# MMC1 register map
Vendor: Texas Instruments
Registers are 32-bit, access per field, reset 0x0 unless marked. A register's access mark holds for its fields unless they carry their own. Offsets are as the file gives them; [hi:lo] are bit positions; {n}, {i} and the like mark numbered series.

## MMC1 (part 2 of 3)
0x00 MMCHS_HL_REV ro reset not defined — IP Revision Identifier (X.Y.R) Used by software to track features, bugs, and compatibility
  [31:0] REVISION — IP Revision
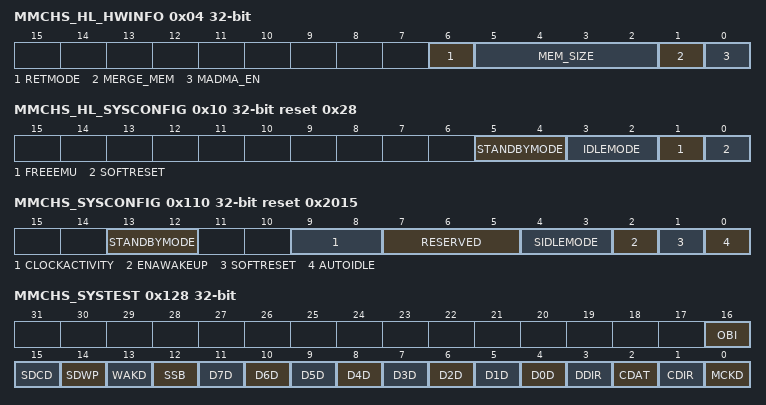
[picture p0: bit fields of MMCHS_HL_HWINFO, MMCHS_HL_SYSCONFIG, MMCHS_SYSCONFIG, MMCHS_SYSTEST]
0x04 MMCHS_HL_HWINFO ro reset not defined — Information about the IP module's hardware configuration.
  [6] RETMODE — Retention Mode generic parameter This bit field indicates whether the retention mode is supported using the pin PIRFFRET.
    1=RetEnabled (Retention mode enabled); 0=RetDisabled (Retention mode disabled)
  [5:2] MEM_SIZE — Memory size for FIFO buffer:
    2=MEM_1024 (Memory of 1024 bytes, max block length is 1024 bytes); 1=MEM_512 (Memory of 512 bytes, max block length is 512 bytes); 8=MEM_4096 (Memory of 4096 bytes, max block length is 2048 bytes); 4=MEM_2048 (Memory of 2048 bytes, max block length is 2048 bytes)
  [1] MERGE_MEM — Memory merged for FIFO buffer: This register defines the configuration of FIFO buffer architecture. If the bit is set STA and DFT shall support clock multiplexing and balancing.
    1=SingleMemBuffer (A single memory is used with multiplexed addresses, data and clocks.); 0=TwoMemBuffer (2 memories instantiated, one per data transfer direction.)
  [0] MADMA_EN — Master DMA enabled generic parameter: This register defines the configuration of the controller to know if it supports the master DMA management called ADMA.
    1=SupportADMA (Controller supports ADMA); 0=No Master DMA (ADMA) management supported
0x10 MMCHS_HL_SYSCONFIG reset 0x28 — Clock Management Configuration Register
  [5:4] STANDBYMODE rw — Configuration of the local initiator state management mode. By definition, initiator may generate read/write transaction as long as it is out of STANDBY state.
    0=Force-standby mode: local initiator is unconditionally placed in standby state.Backup mode, for debug only; 1=No-standby mode: local initiator is unconditionally placed out of standby state.Backup mode, for debug only; 3=Smart-Standby wakeup-capable mode: local initiator standby status depends on local conditions, i.e. the module's functional requirement from the initiator. IP module may generate (master-related) wakeup events when in standby state.Mode is only relevant if the appropriate IP module 'mwakeup' output is implemented.; 2=Smart-standby mode: local initiator standby status depends on local conditions, i.e. the module's functional requirement from the initiator.IP module shall not generate (initiator-related) wakeup events.
  [3:2] IDLEMODE rw — Configuration of the local target state management mode. By definition, target can handle read/write transaction as long as it is out of IDLE state.
    0=Force-idle mode: local target's idle state follows (acknowledges) the system's IDLE requests unconditionally, i.e. regardless of the IP module's internal requirements.Backup mode, for debug only.; 1=No-idle mode: local target never enters idle state.Backup mode, for debug only; 3=Smart-idle wakeup-capable mode: local target's idle state eventually follows (acknowledges) the system's IDLE requests, depending on the IP module's internal requirements.IP module may generate (IRQ- or DMA-request-related) wakeup events when in idle state.Mode is only relevant if the appropriate IP module 'swakeup' output(s) is (are) implemented; 2=Smart-idle mode: local target's idle state eventually follows (acknowledges) the system's IDLE requests, depending on the IP module's internal requirements.IP module shall not generate (IRQ- or DMA-request-related) wakeup events
  [1] FREEEMU rw — Sensitivity to emulation (debug) suspend input signal. Functionality NOT implemented in MMCHS.
    0=EmuEn (IP module is sensitive to emulation suspend); 1=EmuDis (IP module is not sensitive to emulation suspend)
  [0] SOFTRESET rw — Software reset. (Optional)
    0=NoAction; 1=SoftReset (Initiate software reset); 1=ResetOnGoing (Reset (software or other) ongoing); 0=Reset done, no pending action
0x110 MMCHS_SYSCONFIG reset 0x2015 — System Configuration Register This register allows controlling various parameters of the Interconnect interface.
  [13:12] STANDBYMODE rw — Master interface power Management, standby/wait control. The bit field is only useful when generic parameter MMCHS_HL_HWINFO[0] MADMA_EN (Master ADMA enable) is set as active, otherwise it is a read only register read a '0'.
    0=Force-standby. Mstandby is forced unconditionnaly.; 1=NoIdle (No-standby. Mstandby is never asserted.); 2=Smart-standby mode: local initiator standby status depends on local conditions, i.e. the module's functional requirement from the initiator.IP module shall not generate (initiator-related) wakeup events.
  [9:8] CLOCKACTIVITY rw — Clocks activity during wake up mode period. Bit8: Interface clock Bit9: Functional clock
    0=None (Interface and Functional clock may be switched off.); 1=OCP (Interface clock is maintained. Functional clock may be switched-off.); 3=Both (Interface and Functional clocks are maintained.); 2=Functional clock is maintained. Interface clock may be switched-off.
  [7:5] RESERVED ro — This bit is initialized to zero, and writes to it are ignored. Reads return 0.
  [4:3] SIDLEMODE rw — Power management
    0=Force (If an IDLE request is detected, the MMCHS acknowledges it unconditionally and goes in Inactive mode. Interrupt and DMA requests are unconditionally de-asserted.); 1=NoIdle (If an IDLE request is detected, the request is ignored and the module keeps on behaving normally.); 3=SmartWake (Smart-idle wakeup-capable mode: local target's idle state eventually follows (acknowledges) the system's IDLE requests, depending on the IP module's internal requirements.IP module may generate (IRQ- or DMA-request-related) wakeup events when in idle state.Mode is only relevant if the appropriate IP module 'swakeup' output(s) is (are) implemented.); 2=Smart-idle mode: local target's idle state eventually follows (acknowledges) the system's IDLE requests, depending on the IP module's internal requirements.IP module shall not generate (IRQ- or DMA-request-related) wakeup events
  [2] ENAWAKEUP rw — Wakeup feature control
    0=Disabled (Wakeup capability is disabled); 1=Enable (Wakeup capability is enabled)
  [1] SOFTRESET rw — Software reset. The bit is automatically reset by the hardware. During reset, it always returns 0.
    0=St_un_w (No effect.); 1=St_rst_w (Trigger a module reset.); 1=OnReset_r (The module is reset.); 0=NoReset_r (Normal mode)
  [0] AUTOIDLE rw — Internal Clock gating strategy
    0=Off (Clocks are free-running); 1=On (Automatic clock gating strategy is applied, based on the Interconnect and MMC interface activity)
0x114 MMCHS_SYSSTATUS ro — System Status Register This register provides status information about the module excluding the interrupt status information
  [0] RESETDONE — Internal Reset Monitoring Note: the debounce clock , the system clock (Interface) and the functional clock shall be provided to the MMC/SD/SDIO host controller to allow the internal reset monitoring.
    1=Done (Reset completed.); 0=OnGoing (Internal module reset is on-going)
0x124 MMCHS_CSRE rw — Card Status Response Error This register enables the host controller to detect card status errors of response type R1, R1b for all cards and of R5, R5b and R6 response for cards types SD or SDIO. When a bit [i] is set to 1, if the corresponding bit at the same position in the response MMCHS_RSP0[i] is set to 1, the host controller indicates a card error ([CERR]) interrupt status to avoid the host driver reading the response register (MMCHS_RSP0). Note: No automatic card error detection for autoCMD12 is implemented; the host system has to check autoCMD12 response register (MMCHS_RESP76) for possible card errors.
  [31:0] CSRE — Card status response error
0x128 MMCHS_SYSTEST — System Test Register This register is used to control the signals that connect to I/O pins when the module is configured in system test (SYSTEST) mode for boundary connectivity verification. Note: In SYSTEST mode, a write into register will not start a transfer. The buffer behaves as a stack accessible only by the local host (push and pop operations). In this mode, the Transfer Block Size ([BLEN]) and the Blocks count for current transfer ([NBLK]) are needed to generate a Buffer write ready interrupt ([BWR]) or a Buffer read ready interrupt ([BRR]) and DMA requests if enabled.
  [16] OBI ro — Out-Of-Band Interrupt (OBI) data value
    1=HighLevel (The Out-of-Band Interrupt pin is driven high.); 0=LowLevel (The Out-of-Band Interrupt pin is driven low.)
  [15] SDCD ro — Card detect input signal (mmci_sdcd) data value
    1=DrivenHigh (The card detect pin is driven high.); 0=DrivenLow (The card detect pin is driven low.)
  [14] SDWP ro — Write protect input signal (mmci_sdwp) data value
    1=DrivenHigh (The write protect pin mmci_sdwp is driven high.); 0=DrivenLow (The write protect pin mmci_sdwp is driven low.)
  [13] WAKD rw — Wake request output signal data value
    0=DrivenLow_w (The pin SWAKEUP is driven low.); 1=DrivenHIgh_w (The pin SWAKEUP is driven high.); 1=One_r (No action. Returns 1.); 0=Zero_r (No action. Returns 0.)
  [12] SSB rw — Set status bit This bit must be cleared prior attempting to clear a status bit of the interrupt status register (MMCHS_STAT).
    0=Clear_w (Clear this SSB bitfield. Writing 0 does not clear already set status bits;); 1=SetThemAll_w (Force to 1 all status bits of the interrupt status register () only if the corresponding bitfield in the Interrupt signal enable register () is set.); 1=One_r (No action. Returns 1.); 0=Zero_r (No action. Returns 0.)
  [n+4] D{n}D rw (n=1..7) — DAT{n} input/output signal data value
    0=DriveLow_w (If SYSTEST[DDIR] = 0 (output mode direction), the DAT{n} line is driven low. If SYSTEST[DDIR] = 1 (input mode direction), no effect.); 1=DriveHigh_w (If SYSTEST[DDIR] = 0 (output mode direction), the DAT{n} line is driven high. If SYSTEST[DDIR] = 1 (input mode direction), no effect.); 1=One_r (If SYSTEST[DDIR] = 1 (input mode direction), returns the value on the DAT{n} line (high) If SYSTEST[DDIR] = 0 (output mode direction), returns 1); 0=Zero_r (If SYSTEST[DDIR] = 1 (input mode direction), returns the value on the DAT{n} line (low). If SYSTEST[DDIR] = 0 (output mode direction), returns 0)
  [4] D0D rw — DAT0 input/output signal data value
    0=Zero_w (If SYSTEST[DDIR] = 0 (output mode direction), the DAT0 line is driven low. If SYSTEST[DDIR] = 1 (input mode direction), no effect.); 1=DriveHigh_w (If SYSTEST[DDIR] = 0 (output mode direction), the DAT0 line is driven high. If SYSTEST[DDIR] = 1 (input mode direction), no effect.); 1=One_r (If SYSTEST[DDIR] = 1 (input mode direction), returns the value on the DAT0 line (high) If SYSTEST[DDIR] = 0 (output mode direction), returns 1); 0=Zero_r (If SYSTEST[DDIR] = 1 (input mode direction), returns the value on the DAT0 line (low). If SYSTEST[DDIR] = 0 (output mode direction), returns 0)
  [3] DDIR rw — Control of the DAT[7:0] pins direction.
    0=Out_w (The DAT lines are outputs (host to card)); 1=In_w (The DAT lines are inputs (card to host)); 1=One_r (No action. Returns 1.); 0=Zero_r (No action. Returns 0.)
  [2] CDAT rw — CMD input/output signal data value
    0=DriveLow_w (If SYSTEST[CDIR] = 0 (output mode direction), the CMD line is driven low. If SYSTEST[CDIR] = 1 (input mode direction), no effect.); 1=DriveHigh_w (If SYSTEST[CDIR] = 0 (output mode direction), the CMD line is driven high. If SYSTEST[CDIR] = 1 (input mode direction), no effect.); 1=One_r (If SYSTEST[CDIR] = 1 (input mode direction), returns the value on the CMD line (high) If SYSTEST[CDIR] = 0 (output mode direction), returns 1); 0=Zero_r (If SYSTEST[CDIR] = 1 (input mode direction), returns the value on the CMD line (low). If SYSTEST[CDIR] = 0 (output mode direction), returns 0)
  [1] CDIR rw — Control of the CMD pin direction.
    0=Out_w (The CMD line is an output (host to card)); 1=In_w (The CMD line is an input (card to host)); 1=One_r (No action. Returns 1.); 0=Zero_r (No action. Returns 0.)
  [0] MCKD rw — MMC clock output signal data value
    0=DrivenLow_w (The output clock is driven low.); 1=DrivenHigh_w (The output clock is driven high.); 1=One_r (No action. Returns 1.); 0=Zero_r (No action. Returns 0.)
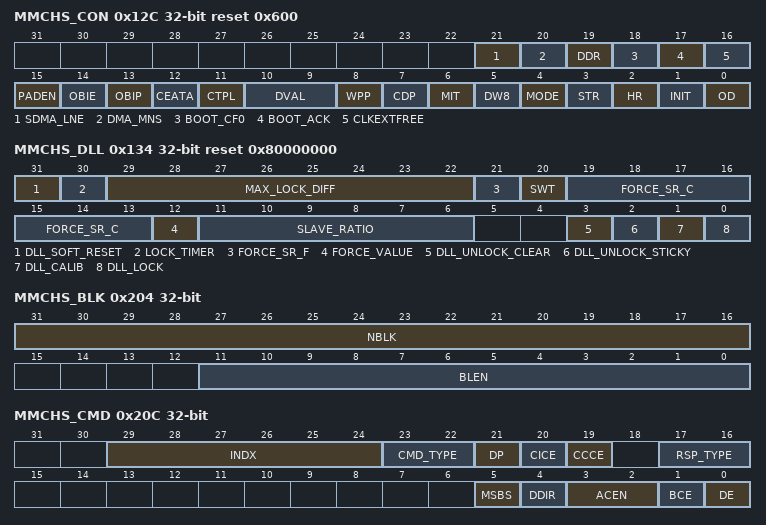
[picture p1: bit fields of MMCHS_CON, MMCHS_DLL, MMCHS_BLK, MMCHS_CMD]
0x12C MMCHS_CON reset 0x600 — Configuration Register This register is used: - to select the functional mode or the SYSTEST mode for any card. - to send an initialization sequence to any card. - to enable the detection on DAT[1] of a card interrupt for SDIO cards only. and also to configure : - specific data and command transfers for MMC cards only. - the parameters related to the card detect and write protect input signals.
  [21] SDMA_LNE rw — Slave DMA Level/Edge Request: The waveform of the DMA request can be configured either edge sensitive with early de-assertion on first access to MMCHS_DATA register or late de-assertion, request remains active until last allowed data written into MMCHS_DATA.
    0=EarlyDeAssert (Slave DMA edge sensitive, Early DMA de-assertion); 1=LateDeAssert (Slave DMA level sensitive, Late DMA de-assertion)
  [20] DMA_MNS rw — DMA Master or Slave selection: When this bit is set and the controller is configured to use the DMA, Interconnect master interface is used to get datas from system using ADMA2 procedure (direct access to the memory).This option is only available if generic parameter MADMA_EN is asserted to '1'.
    0=MasterDMADis (The controller is slave on data transfers with system.); 1=MasterDMAEn (The controller is master on data exchange with system, controller must be configured as using DMA.)
  [19] DDR rw — Dual Data Rate mode: When this register is set, the controller uses both clock edge to emit or receive data. Odd bytes are transmitted on falling edges and even bytes are transmitted on rise edges. It only applies on Data bytes and CRC, Start, end bits and CRC status are kept full cycle. This bit field is only meaningful and active for even clock divider ratio of MMCHS_SYSCTL[CLKD], it is insensitive to MMCHS_HCTL[HSPE] setting.
    0=NormalMode (Standard mode : data are transmitted on a single edge depending on MMCHS_HCTRL[HSPE].); 1=DDRMode (Data Bytes and CRC are transmitted on both edge.)
  [18] BOOT_CF0 rw — Boot status supported: This register is set when the CMD line need to be forced to '0' for a boot sequence. CMD line is driven to '0' after writing in MMCHS_CMD. The line is released when this bit field is de-asserted and abort data transfer in case of a pending transaction.
    0=CMDReleased (CMD line is released when it was previously forced to '0' by a boot sequence.); 1=CMDForceReq (CMD line forced to '0' is enabled and will be active after writing into); 1=CMDForced (CMD line forced to '0' is enabled); 0=NoCMDForce (CMD line not forced)
  [17] BOOT_ACK rw — Boot acknowledge received: When this bit is set the controller should receive a boot status on DAT0 line after next command issued. If no status is received a data timeout will be generated.
    0=BootNoAck (No acknowledge to be received); 1=BootAck (A boot status will be received on DAT0 line after issuing a command.)
  [16] CLKEXTFREE rw — External clock free running: This register is used to maintain card clock out of transfer transaction to enable slave module for example to generate a synchronous interrupt on DAT[1]. The Clock will be maintain only if MMCHS_SYSCTL[CEN] is set.
    0=Autogating (External card clock is cut off outside active transaction period.); 1=FreeRunning (External card clock is maintain even out of active transaction period only if[CEN] is set.)
  [15] PADEN rw — Control Power for MMC Lines: This register is only useful when MMC PADs contain power saving mechanism to minimize its leakage power. It works as a GPIO that directly control the ACTIVE pin of PADs. Excepted for DAT[1], the signal is also combine outside the module with the dedicated power control MMCHS_CON[CTPL] bit.
    0=Disable (ADPIDLE module pin is not forced, it is automatically generated by the MMC fsms.); 1=Enable (ADPIDLE module pin is forced to active state.)
  [14] OBIE rw — Out-of-Band Interrupt Enable MMC cards only: This bit enables the detection of Out-of-Band Interrupt on MMCOBI input pin. The usage of the Out-of-Band signal (OBI) is optional and depends on the system integration.
    0=NormalMode (Out-of-Band interrupt detection disabled); 1=OBintMode (Out-of-Band interrupt detection enabled)
  [13] OBIP rw — Out-of-Band Interrupt Polarity MMC cards only: This bit selects the active level of the out-of-band interrupt coming from MMC cards. The usage of the Out-of-Band signal (OBI) is optional and depends on the system integration.
    0=Active high level; 1=Active low level
  [12] CEATA rw — CE-ATA control mode MMC cards compliant with CE-ATA:By default, this bit is set to 0. It is used to indicate that next commands are considered as specific CE-ATA commands that potentially use 'command completion' features.
    0=NormalMode (Standard MMC/SD/SDIO mode.); 1=CE-ATA mode next commands are considered as CE-ATA commands
  [11] CTPL rw — Control Power for DAT[1] line MMC and SD cards: By default, this bit is set to 0 and the host controller automatically disables all the input buffers outside of a transaction to minimize the leakage current. SDIO cards: When this bit is set to 1, the host controller automatically disables all the input buffers except the buffer of DAT[1] outside of a transaction in order to detect asynchronous card interrupt on DAT[1] line and minimize the leakage current of the buffers.
    0=MMC_SD (Disable all the input buffers outside of a transaction.); 1=SDIO (Disable all the input buffers except the buffer of DAT[1] outside of a transaction.)
  [10:9] DVAL rw — Debounce filter value All cards This register is used to define a debounce period to filter the card detect input signal (mmci_sdcd). The usage of the card detect input signal (mmci_sdcd) is optional and depends on the system integration and the type of the connector housing that accommodates the card.
    0=FilterLevel0 (33 us debounce period); 1=FilterLevel1 (231 us debounce period); 3=FilterLevel3 (8,4 ms debounce period); 2=FilterLevel2 (1 ms debounce period)
  [8] WPP rw — Write protect polarity For SD and SDIO cards only This bit selects the active level of the write protect input signal (mmci_sdwp). The usage of the write protect input signal (mmci_sdwp) is optional and depends on the system integration and the type of the connector housing that accommodates the card.
    0=Active high level; 1=Active low level
  [7] CDP rw — Card detect polarity All cards This bit selects the active level of the card detect input signal (mmci_sdcd). The usage of the card detect input signal (mmci_sdcd) is optional and depends on the system integration and the type of the connector housing that accommodates the card.
    0=ActiveHigh (Active low level); 1=ActiveLow (Active high level)
  [6] MIT rw — MMC interrupt command Only for MMC cards. This bit must be set to 1, when the next write access to the command register (MMCHS_CMD) is for writing a MMC interrupt command (CMD40) requiring the command timeout detection to be disabled for the command response.
    0=CTO (Command timeout enabled); 1=No_CTO (Command timeout disabled)
  [5] DW8 rw — 8-bit mode MMC select For SD/SDIO cards, this bit must be set to 0. For MMC card, this bit must be set following a valid SWITCH command (CMD6) with the correct value and extend CSD index written in the argument. Prior to this command, the MMC card configuration register (CSD and EXT_CSD) must be verified for compliancy with MMC standard specification 4.x (see section 3.6).
    0=1_4BitMode (1-bit or 4-bit Data width (DAT[0] used, MMC, SD cards)); 1=8BitMode (8-bit Data width (DAT[7:0] used, MMC cards))
  [4] MODE rw — Mode select All cards This bit select between Functional mode and SYSTEST mode.
    0=FUNC (Functional mode. Transfers to the MMC/SD/SDIO cards follow the card protocol. MMC clock is enabled. MMC/SD transfers are operated under the control of the CMD register.); 1=SYSTEST (SYSTEST mode The signal pins are configured as general-purpose input/output and the 1024-byte buffer is configured as a stack memory accessible only by the local host or system DMA. The pins retain their default type (input, output or in-out). SYSTEST mode is operated under the control of the SYSTEST register.)
  [3] STR rw — Stream command Only for MMC cards. This bit must be set to 1 only for the stream data transfers (read or write) of the adtc commands. Stream read is a class 1 command (CMD11: READ_DAT_UNTIL_STOP). Stream write is a class 3 command (CMD20: WRITE_DAT_UNTIL_STOP).
    0=Block oriented data transfer; 1=Stream oriented data transfer
  [2] HR rw — Broadcast host response Only for MMC cards. This register is used to force the host to generate a 48-bit response for bc command type. It can be used to terminate the interrupt mode by generating a CMD40 response by the core (see section 4.3, 'Interrupt Mode', in the MMC specification). In order to have the host response to be generated in open drain mode, the register MMCHS_CON[OD] must be set to 1. When MMCHS_CON[CEATA] is set to 1 and MMCHS_ARG set to 0x00000000 when writing 0x00000000 into MMCHS_CMD register, the host controller performs a 'command completion signal disable' token i.e. CMD line held to '0' during 47 cycles followed by a 1.
    0=NoHostResp (The host does not generate a 48-bit response instead of a command.); 1=HostResp (The host generates a 48-bit response instead of a command or a command completion signal disable token.)
  [1] INIT rw — Send initialization stream All cards. When this bit is set to 1, and the card is idle, an initialization sequence is sent to the card. An initialization sequence consists of setting the CMD line to 1 during 80 clock cycles. The initialisation sequence is mandatory - but it is not required to do it through this bit - this bit makes it easier. Clock divider (MMCHS_SYSCTL[CLKD]) should be set to ensure that 80 clock periods are greater than 1ms. (see section 9.3, 'Power-Up', in the MMC card specification, or section 6.4 in the SD card specification). Note: in this mode, there is no command sent to the card and no response is expected
    0=NoInit (The host does not send an initialization sequence.); 1=InitStream (The host sends an initialization sequence.)
  [0] OD rw — Card open drain mode. Only for MMC cards. This bit must be set to 1 for MMC card commands 1, 2, 3 and 40, and if the MMC card bus is operating in open-drain mode during the response phase to the command sent. Typically, during card identification mode when the card is either in idle, ready or ident state. It is also necessary to set this bit to 1, for a broadcast host response (see Broadcast host response register MMCHS_CON[HR])
    0=NoOpenDrain; 1=Open Drain or Broadcast host response
0x130 MMCHS_PWCNT — Power Counter Register This register is used to program a mmc counter to delay command transfers after activating the PAD power, this value depends on PAD characteristics and voltage.
  [15:0] PWRCNT rw — Power counter register. This register is used to introduce a delay between the PAD ACTIVE pin assertion and the command issued.
    0xFFFF=65535cycles (TCF x 65535 delay (card clock period)); 0=nodelay (No additional delay added); 1=1cycles (TCF delay (card clock period)); 0xFFFE=65534cycles (TCF x 65534 delay (card clock period)); 2=2cycles (TCF x 2 delay (card clock period))
0x134 MMCHS_DLL reset 0x80000000 — DLL control and status register This register is used for tuning procedure required for SDR104/HS200 speed mode. It gives visibility and control on the DLL
  [31] DLL_SOFT_RESET rw — Soft reset for DLL, active HIGH.
    0=Write_0 (No action.); 1=Write_1 (Issue soft reset); 1=Read_1 (Reset is in progress); 0=Read_0 (Reset completed.)
  [30] LOCK_TIMER rw — Timer for the dll_lock signal to be asserted after reset.
    0=DLL_FAST_MODE (1024 cycles (equivalent to DLL fast mode lock)); 1=Other (66560 cycles)
  [29:22] MAX_LOCK_DIFF rw — Maximum number of taps that the master DLL clock period measurement can deviate without resulting in the master DLL losing lock.
  [21] FORCE_SR_F rw — Forced fine delay value.
  [20] SWT rw — Software Tuning enable. The bit shall be set to manage the tuning sequence fully in software. NOTE: For proper operation when SDR104/HS200 mode is used this bit must be set to 0x1 which disables the Conflict Error (CFT Error) on the CMD line. 0x0: No software tuning sequence. 0x1: Execute software tuning sequence.
  [19:13] FORCE_SR_C rw — Forced coarse delay value
  [12] FORCE_VALUE rw — Put forced values to slave DLL, ignoring master DLL output and ratio value.
    0=No_force (Do not put force value); 1=Force (Put force value.)
  [11:6] SLAVE_RATIO rw — Fraction of a clock cycle for the shift to be implemented, in units of 256ths of a clock cycle.
    6=plus135 (135 degrees delay); 63=fourcycles (4 clocks delay); 8=plus180 (180 degrees delay); 2=plus45 (45 degrees delay); 10=plus225 (225 degrees delay); 16=plus380 (Full clock delay); 0=plus0 (0 degree delay); 12=plus270 (270 degrees delay); 4=plus90 (90 degrees delay); 14=plus315 (315 degrees delay)
  [3] DLL_UNLOCK_CLEAR rw — Clears the phy_reg_status_mdll_unlock_sticky flags of the DLL.
    0=No effect; 1=Clears the flag
  [2] DLL_UNLOCK_STICKY ro — Asserted when any single period measurement exceeds MAX_LOCK_DIFF.
  [1] DLL_CALIB rw — Enables Slave DLL to update new delay values.
    0=Disabled; 1=Enabled
  [0] DLL_LOCK ro — Master DLL lock status.
    1=Locked (DLL is locked); 0=NotLocked (DLL is not locked)
0x200 MMCHS_SDMASA rw — SDMA System Address / Argument 2 Register
  [31:0] SDMA_ARG2 — SDMA System Address / Argument 2 This register contains the physical system memory address used for DMA transfers or the second argument for the Auto CMD23. (1) SDMA System Address This register contains the system memory address for a SDMA transfer. When the Host Controller stops a SDMA transfer, this register shall point to the system address of the next contiguous data position. It can be accessed only if no transaction is executing (i.e., after a transaction has stopped). Read operations during transfers may return an invalid value. The Host Driver shall initialize this register before starting a SDMA transaction. After SDMA has stopped, the next system address of the next contiguous data position can be read from this register. The SDMA transfer waits at the every boundary specified by the Host SDMA Buffer Boundary in the Block Size register. The Host Controller generates DMA Interrupt to request the Host Driver to update this register. The Host Driver sets the next system address of the next data position to this register. When the most upper byte of this register (003h) is written, the Host Controller restarts the SDMA transfer. When restarting SDMA by the Resume command or by setting Continue Request in the Block Gap Control register, the Host Controller shall start at the next contiguous address stored here in the SDMA System Address register. ADMA does not use this register. (2) Argument 2 This register is used with the Auto CMD23 to set a 32-bit block count value to the argument of the CMD23 while executing Auto CMD23. If Auto CMD23 is used with ADMA, the full 32-bit block count value can be used. If Auto CMD23 is used without AMDA, the available block count value is limited by the Block Count register. 65535 blocks is the maximum value in this case.
0x204 MMCHS_BLK — Transfer Length Configuration Register [BLEN] is the block size register. [NBLK] is the block count register. This register shall be used for any card.
  [31:16] NBLK rw — Blocks count for current transfer This register is enabled when Block count Enable (MMCHS_CMD[BCE]) is set to 1 and is valid only for multiple block transfers. Setting the block count to 0 results no data blocks being transferred. Note: The host controller decrements the block count after each block transfer and stops when the count reaches zero. This register can be accessed only if no transaction is executing (i.e, after a transaction has stopped). Read operations during transfers may return an invalid value and write operation will be ignored. In suspend context, the number of blocks yet to be transferred can be determined by reading this register. When restoring transfer context prior to issuing a Resume command, The local host shall restore the previously saved block count.
    0xFFFF=65535blks (65535 blocks); 0=Stpcnt (Stop count); 1=1blk (1 block); 2=2blks (2 blocks)
  [11:0] BLEN rw — Transfer Block Size. This register specifies the block size for block data transfers. Read operations during transfers may return an invalid value, and write operations are ignored. When a CMD12 command is issued to stop the transfer, a read of the BLEN field after transfer completion (MMCHS_STAT[TC] set to 1) will not return the true byte number of data length while the stop occurs but the value written in this register before transfer is launched.
    1=1bytelen (1 byte block length); 0x7FF=2047byteslen (2047 bytes block length); 0=Notransfer (No data transfer); 0x1FF=511byteslen (511 bytes block length); 0x800=2048byteslen (2048 bytes block length); 2=2byteslen (2 bytes block length); 3=3byteslen (3 bytes block length); 0x200=512byteslen (512 bytes block length)
0x208 MMCHS_ARG rw — Command Argument Register This register contains command argument specified as bit 39-8 of Command-Format These registers must be initialized prior to sending the command itself to the card (write action into the register register). Only exception is for a command index specifying stuff bits in arguments, making a write unnecessary.
  [31:0] ARG — Command argument bits [31:0]
0x20C MMCHS_CMD — Command and Transfer Mode Register [31:16] = the command register [15:0] = the transfer mode. This register configures the data and command transfers. A write into the most significant byte send the command. A write into [15:0] registers during data transfer has no effect. This register shall be used for any card. Note: In SYSTEST mode, a write into register will not start a transfer.
  [29:24] INDX rw — Command indexBinary encoded value from 0 to 63 specifying the command number send to card .
    {v}=CMD{v} (CMD{v} or ACMD{v}) (v=0..63)
  [23:22] CMD_TYPE rw — Command typeThis register specifies three types of special command: Suspend, Resume and Abort. . These bits shall be set to 00b for all other commands. .
    0=Normal (Others Commands); 1=Suspend (CMD52 for writing 'Bus Suspend' in CCCR); 3=Abort command CMD12, CMD52 for writing ' I/O Abort' in CCCR; 2=Resume (CMD52 for writing 'Function Select' in CCCR)
  [21] DP rw — Data present selectThis register indicates that data is present and DAT line shall be used. . It must be set to 0 in the following conditions: . - command using only CMD line . - command with no data transfer but using busy signal on DAT[0] . - Resume command .
    0=NoData (Command with no data transfer); 1=Data (Command with data transfer)
  [20] CICE rw — Command Index check enableThis bit must be set to 1 to enable index check on command response to compare the index field in the response against the index of the command. . If the index is not the same in the response as in the command, it is reported as a command index error ([CIE] set to1). . Note:The register CICE cannot be configured for an Auto CMD12, then index check is automatically checked when this command is issued. .
    0=Nocheck (Index check disable); 1=Check (Index check enable)
  [19] CCCE rw — Command CRC check enableThis bit must be set to 1 to enable CRC7 check on command response to protect the response against transmission errors on the bus. . If an error is detected, it is reported as a command CRC error ([CCRC] set to 1). . Note: The register CCCE cannot be configured for an Auto CMD12, and then CRC check is automatically checked when this command is issued. .
    0=NoCheck (CRC7 check disable); 1=Check (CRC7 check enable)
  [17:16] RSP_TYPE rw — Response typeThis bits defines the response type of the command .
    0=Norsp (No response); 1=Lght36 (Response Length 136 bits); 3=Lght48b (Response Length 48 bits with busy after response); 2=Lght48 (Response Length 48 bits)
  [5] MSBS rw — Multi/Single block selectThis bit must be set to 1 for data transfer in case of multi block command. . For any others command this bit shall be set to 0. . If this bit is 0, it is not necessary to set the register[NBLK]. enum=sgleblk . When Block Count is disabled ([BCE] is set to 0) in Multiple block transfers ([MSBS] is set to 1), the module can perform infinite transfer. enum=multiblk .
    0=Single_block; 1=multiblk (Multi block.)
  [4] DDIR rw — Data transfer Direction SelectThis bit defines either data transfer will be a read or a write. .
    0=Write (Data Write (host to card)); 1=Read (Data Read (card to host))
  [3:2] ACEN rw — Auto CMD Enable - SD card only.This field determines use of auto command functions. . There are two methods to stop Multiple-block read and write operation . – Auto CMD23 Supported (Host Controller Version is 3.00 or later) . – A memory card that supports CMD23 (SCR[33]=1) . – If DMA is used, it shall be ADMA. . –Only when CMD18 or CMD25 is issued . (Note: the Host Controller does not check command index.) . Auto CMD23 can be used with or without ADMA. By writing the Command register, the Host Controller issues a CMD23 first and then issues a command specified by the Command Index in Command register. If response errors of CMD23 are detected, the second command is not issued. A CMD23 error is indicated in the Auto CMD Error Status register (). 32-bit block count value for CMD23 is set to SDMA System Address / Argument 2 register (). .
    0=Disable (Auto Command Disabled); 1=EnableCMD12 (Auto CMD12 enable or CCS detection enabled.); 2=EnableCMD23 (Auto CMD23 Enable)
  [1] BCE rw — Block Count EnableMultiple block transfers only. . This bit is used to enable the block count register ([NBLK]). . When Block Count is disabled ([BCE] is set to 0) in Multiple block transfers ([MSBS] is set to 1), the module can perform infinite transfer. .
    0=Disable (Block count disabled for infinite transfer.); 1=Enable (Block count enabled for multiple block transfer with known number of blocks)
  [0] DE rw — DMA EnableThis bit is used to enable DMA mode for host data access. .
    0=Disable (DMA mode disable); 1=Enable (DMA mode enable)
